AUTOSAR XML (schema 4-0-3)
package /Toplevelbrakecomposition
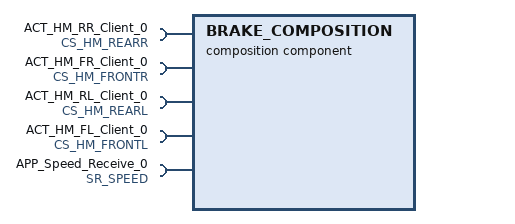
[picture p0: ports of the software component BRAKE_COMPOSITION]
  composition sw component type BRAKE_COMPOSITION
    5 x require port:
      ACT_HM_RR_Client_0: required-interface=CS_HM_REARR
      ACT_HM_FR_Client_0: required-interface=CS_HM_FRONTR
      ACT_HM_RL_Client_0: required-interface=CS_HM_REARL
      ACT_HM_FL_Client_0: required-interface=CS_HM_FRONTL
      APP_Speed_Receive_0: required-interface=SR_SPEED
    5 x component:
      CPT_ACT_HYDRAULIC_MODULATOR_REARR_COMP: type=ACT_HYDRAULIC_MODULATOR_REARR_COMP
      CPT_ACT_HYDRAULIC_MODULATOR_REARL_COMP: type=ACT_HYDRAULIC_MODULATOR_REARL_COMP
      CPT_ACT_HYDRAULIC_MODULATOR_FRONTR_COMP: type=ACT_HYDRAULIC_MODULATOR_FRONTR_COMP
      CPT_ACT_HYDRAULIC_MODULATOR_FRONTL_COMP: type=ACT_HYDRAULIC_MODULATOR_FRONTL_COMP
      CPT_APP_BRAKE_CONTROLL_COMP: type=APP_BRAKE_CONTROLL_COMP
    connect CPT_APP_BRAKE_CONTROLL_COMP.APP_FL_Mode_Send -> CPT_ACT_HYDRAULIC_MODULATOR_FRONTL_COMP.ACT_HM_FL_Recv
    connect CPT_APP_BRAKE_CONTROLL_COMP.APP_FR_Mode_Send -> CPT_ACT_HYDRAULIC_MODULATOR_FRONTR_COMP.ACT_HM_FR_Recv
    connect CPT_APP_BRAKE_CONTROLL_COMP.APP_RL_Mode_Send -> CPT_ACT_HYDRAULIC_MODULATOR_REARL_COMP.ACT_HM_RL_Recv
    connect CPT_APP_BRAKE_CONTROLL_COMP.APP_RR_Mode_Send -> CPT_ACT_HYDRAULIC_MODULATOR_REARR_COMP.ACT_HM_RR_Recv
    delegate CPT_ACT_HYDRAULIC_MODULATOR_REARR_COMP.ACT_HM_RR_Client <-> outer port ACT_HM_RR_Client_0
    delegate CPT_ACT_HYDRAULIC_MODULATOR_FRONTR_COMP.ACT_HM_FR_Client <-> outer port ACT_HM_FR_Client_0
    delegate CPT_ACT_HYDRAULIC_MODULATOR_REARL_COMP.ACT_HM_RL_Client <-> outer port ACT_HM_RL_Client_0
    delegate CPT_ACT_HYDRAULIC_MODULATOR_FRONTL_COMP.ACT_HM_FL_Client <-> outer port ACT_HM_FL_Client_0
    delegate CPT_APP_BRAKE_CONTROLL_COMP.APP_Speed_Receive <-> outer port APP_Speed_Receive_0
